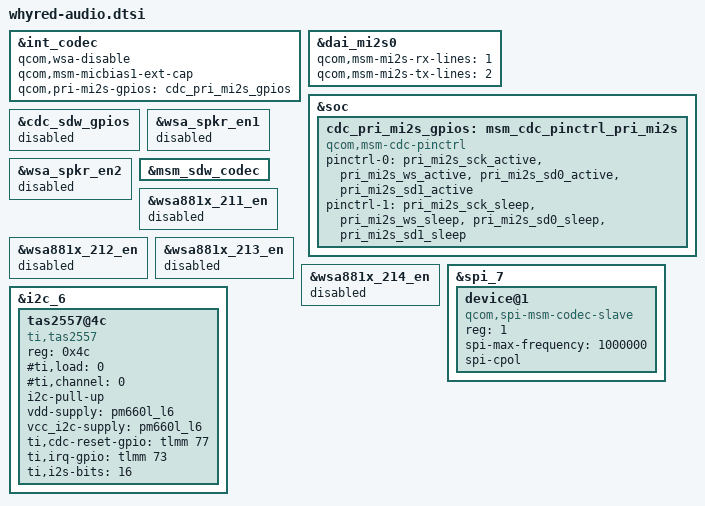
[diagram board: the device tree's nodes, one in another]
/* Copyright (c) 2017, The Linux Foundation. All rights reserved.
 * Copyright (C) 2019 XiaoMi, Inc.
 *
 * This program is free software; you can redistribute it and/or modify
 * it under the terms of the GNU General Public License version 2 and
 * only version 2 as published by the Free Software Foundation.
 *
 * This program is distributed in the hope that it will be useful,
 * but WITHOUT ANY WARRANTY; without even the implied warranty of
 * MERCHANTABILITY or FITNESS FOR A PARTICULAR PURPOSE.  See the
 * GNU General Public License for more details.
*/

&int_codec {
	qcom,wsa-disable;
	qcom,msm-micbias1-ext-cap;
	qcom,pri-mi2s-gpios = <&cdc_pri_mi2s_gpios>;
	/delete-property/ qcom,msm-micbias2-ext-cap;
	/delete-property/ qcom,us-euro-gpios;
};

&dai_mi2s0 {
	qcom,msm-mi2s-rx-lines = <1>;
	qcom,msm-mi2s-tx-lines = <2>;
};

&soc {
	cdc_pri_mi2s_gpios: msm_cdc_pinctrl_pri_mi2s {
		compatible = "qcom,msm-cdc-pinctrl";
		pinctrl-names = "aud_active", "aud_sleep";
		pinctrl-0 = <&pri_mi2s_sck_active &pri_mi2s_ws_active
				&pri_mi2s_sd0_active &pri_mi2s_sd1_active>;
		pinctrl-1 = <&pri_mi2s_sck_sleep &pri_mi2s_ws_sleep
				&pri_mi2s_sd0_sleep &pri_mi2s_sd1_sleep>;
	};
};

&cdc_sdw_gpios {
	status = "disabled";
};

&wsa_spkr_en1 {
	status = "disabled";
};

&wsa_spkr_en2 {
	status = "disabled";
};

&msm_sdw_codec {
	/delete-property/ qcom,cdc-sdw-gpios;
};

&wsa881x_211_en {
	status = "disabled";
};

&wsa881x_212_en {
	status = "disabled";
};

&wsa881x_213_en {
	status = "disabled";
};

&wsa881x_214_en {
	status = "disabled";
};

&spi_7 {
	status = "okay";

	device@1 {
		compatible = "qcom,spi-msm-codec-slave";
		#address-cells = <1>;
		#size-cells = <1>;
		reg = <1>; /* Chip select 0 */
		spi-max-frequency = <1000000>;
		spi-cpol;
	};
};

&i2c_6 { /* SmartPA TI */
	status = "okay";

	tas2557@4c {
		compatible = "ti,tas2557";
		reg = <0x4c>;
		#ti,load = <0>;   /* 0, 8Ohm; 1, 6Ohm; 2, 4Ohm */
		#ti,channel = <0>;   /* 0, left channel; 1, right channel */
		i2c-pull-up;
		vdd-supply = <&pm660l_l6>;
		vcc_i2c-supply = <&pm660l_l6>;
		ti,cdc-reset-gpio = <&tlmm 77 0>;
		ti,irq-gpio = <&tlmm 73 0>;
		ti,i2s-bits = <16>;
		status = "ok";
	};
};
